# R9A09G057H register map
Vendor: Renesas Electronics; File version: 1.00
CPU: other r0p3, little endian, MPU, FPU, vendor SysTick, 4 interrupt priority bits, 480 interrupts
Registers are 32-bit, read-write, no defined reset value unless marked. A register's access mark holds for its fields unless they carry their own. Offsets are from the block's base; [hi:lo] are bit positions; lines under a group give offsets from that group; {n}, {i} and the like mark numbered series.

## R_TSU_B0 — IO define file for tsu_b.
Base 0x11000000
Same registers: R_TSU_B1 0x14002000
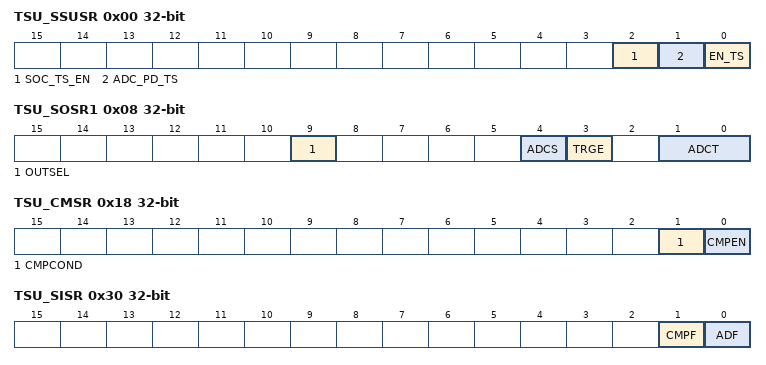
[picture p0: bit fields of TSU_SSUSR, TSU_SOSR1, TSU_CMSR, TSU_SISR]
0x00 TSU_SSUSR
  [2] SOC_TS_EN, [1] ADC_PD_TS, [0] EN_TS
0x04 TSU_STRGR
  [0] ADST wo
0x08 TSU_SOSR1
  [9] OUTSEL, [4] ADCS, [3] TRGE, [1:0] ADCT
0x10 TSU_SCRR ro
  [11:0] OUT12BIT_TS
0x14 TSU_SSR ro
  [0] CONV
0x18 TSU_CMSR
  [1] CMPCOND, [0] CMPEN
0x1C TSU_LLSR
  [11:0] LLIM
0x20 TSU_ULSR
  [11:0] ULIM
0x30 TSU_SISR ro
  [1] CMPF, [0] ADF
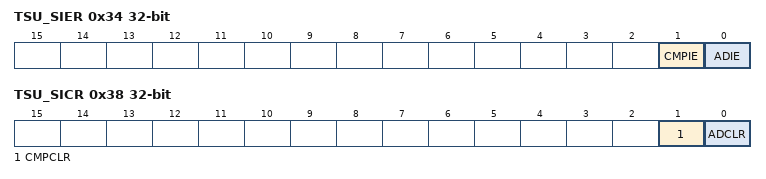
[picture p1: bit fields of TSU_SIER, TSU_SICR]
0x34 TSU_SIER
  [1] CMPIE, [0] ADIE
0x38 TSU_SICR
  [1] CMPCLR wo, [0] ADCLR wo

## R_TZC_SRAMM — IO define file for tzc.
Base 0x10460000
Same registers: R_TZC_XSPI 0x10470000, R_TZC_DDR00 0x13C60000, R_TZC_DDR01 0x13C70000, R_TZC_DDR10 0x13C80000, R_TZC_DDR11 0x13C90000, R_TZC_AXI_RCPU 0x13CA0000, R_TZC_SRAMA 0x13CB0000, R_TZC_PCIE 0x13CC0000
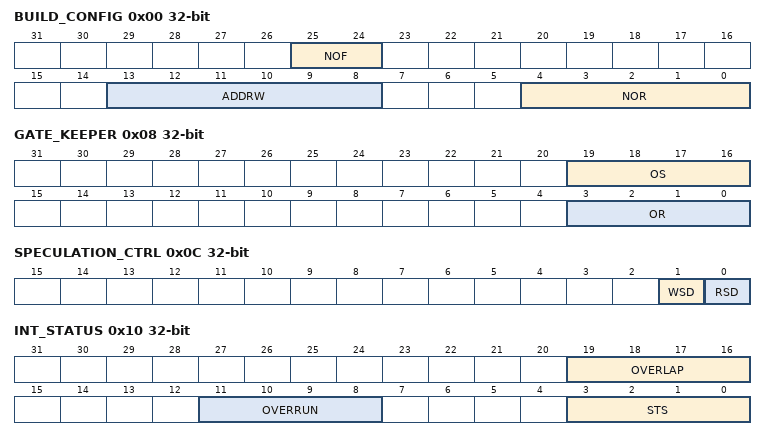
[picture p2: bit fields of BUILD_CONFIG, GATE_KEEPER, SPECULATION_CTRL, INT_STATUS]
0x00 BUILD_CONFIG ro
  [25:24] NOF, [13:8] ADDRW, [4:0] NOR
0x04 ACTION
  [1:0] RV
0x08 GATE_KEEPER
  [19:16] OS, [3:0] OR
0x0C SPECULATION_CTRL
  [1] WSD, [0] RSD
0x10 INT_STATUS ro
  [19:16] OVERLAP, [11:8] OVERRUN, [3:0] STS
0x14 INT_CLEAR wo
  [3:0] CLEAR
{0x20+0x10*i} FAIL_ADDRESS_LOW_{i} ro (i=0..3)
  [31:0] ASL
{0x24+0x10*i} FAIL_ADDRESS_HIGH_{i} ro (i=0..3)
  [0] ASH
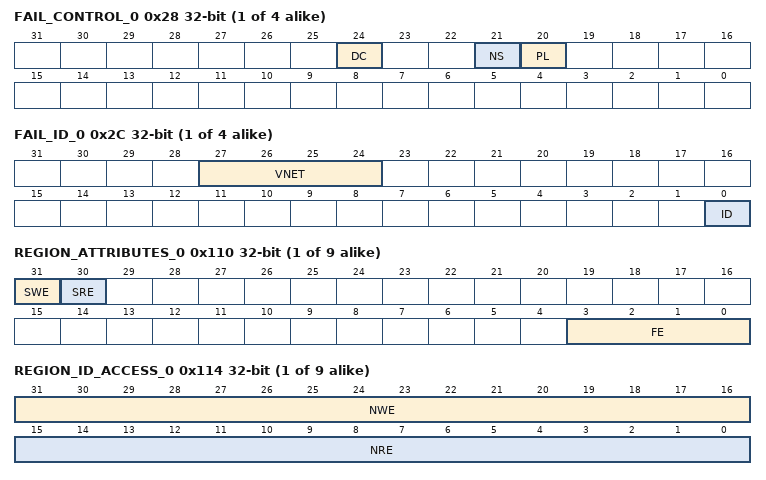
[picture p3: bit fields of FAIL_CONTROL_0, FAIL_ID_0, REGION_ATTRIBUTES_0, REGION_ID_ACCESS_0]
{0x28+0x10*i} FAIL_CONTROL_{i} ro (i=0..3)
  [24] DC, [21] NS, [20] PL
{0x2C+0x10*i} FAIL_ID_{i} ro (i=0..3)
  [27:24] VNET, [0] ID
{0x100+0x20*i} REGION_BASE_LOW_{i} ro (i=0..8)
  [31:12] BAL
0x104 REGION_BASE_HIGH_0 ro
  [0] BAH
{0x108+0x20*i} REGION_TOP_LOW_{i} ro (i=0..8)
  [31:12] TAL
0x10C REGION_TOP_HIGH_0 ro
  [0] TAH
{0x110+0x20*i} REGION_ATTRIBUTES_{i} (i=0..8)
  [31] SWE, [30] SRE, [3:0] FE
{0x114+0x20*i} REGION_ID_ACCESS_{i} (i=0..8)
  [31:16] NWE, [15:0] NRE
{0x104+0x20*i} REGION_BASE_HIGH_{i} ro (i=1..8)
  [{i}:0] BAH
{0x10C+0x20*i} REGION_TOP_HIGH_{i} ro (i=1..8)
  [{i}:0] TAH
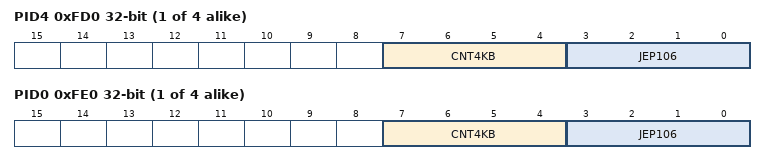
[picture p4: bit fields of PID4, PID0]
{0xFC0+4i} PID{i} ro (i=4..7)
  [7:4] CNT4KB, [3:0] JEP106
{0xFE0+4i} PID{i} ro (i=0..3)
  [7:4] CNT4KB, [3:0] JEP106
{0xFF0+4i} CID{i} ro (i=0..3)
  [7:0] CPI{i}

## R_WDT0 — IO define file for wdt.
Base 0x11C00400
Same registers: R_WDT2 0x13000000, R_WDT3 0x13000400, R_WDT1 0x14400000
0x00 WDT0_WDTRR 8-bit
  [7:0] REFRESH
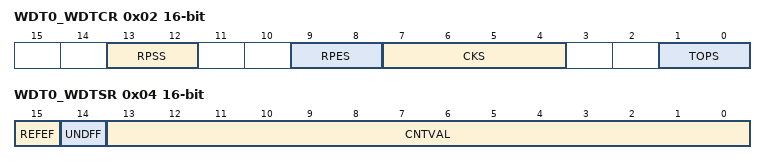
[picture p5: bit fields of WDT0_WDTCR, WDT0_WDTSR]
0x02 WDT0_WDTCR 16-bit
  [13:12] RPSS, [9:8] RPES, [7:4] CKS, [1:0] TOPS
0x04 WDT0_WDTSR 16-bit
  [15] REFEF, [14] UNDFF, [13:0] CNTVAL ro
0x06 WDT0_WDTRCR 8-bit
  [7] RSTIRQS

## R_XSPI0 — IO define file for xspi.
Base 0x11030000
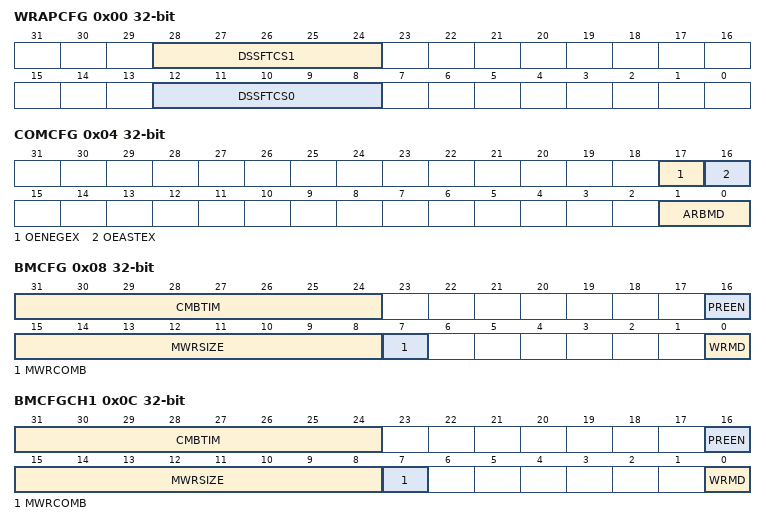
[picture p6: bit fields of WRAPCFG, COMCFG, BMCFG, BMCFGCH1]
0x00 WRAPCFG
  [28:24] DSSFTCS1, [12:8] DSSFTCS0
0x04 COMCFG
  [17] OENEGEX, [16] OEASTEX, [1:0] ARBMD
0x08 BMCFG
  [31:24] CMBTIM, [16] PREEN, [15:8] MWRSIZE, [7] MWRCOMB, [0] WRMD
0x0C BMCFGCH1
  [31:24] CMBTIM, [16] PREEN, [15:8] MWRSIZE, [7] MWRCOMB, [0] WRMD
{0x10+0x10*i} CSa[{i}] (i=0..1) group — xSPI Command Map Configuration Register [0..1]
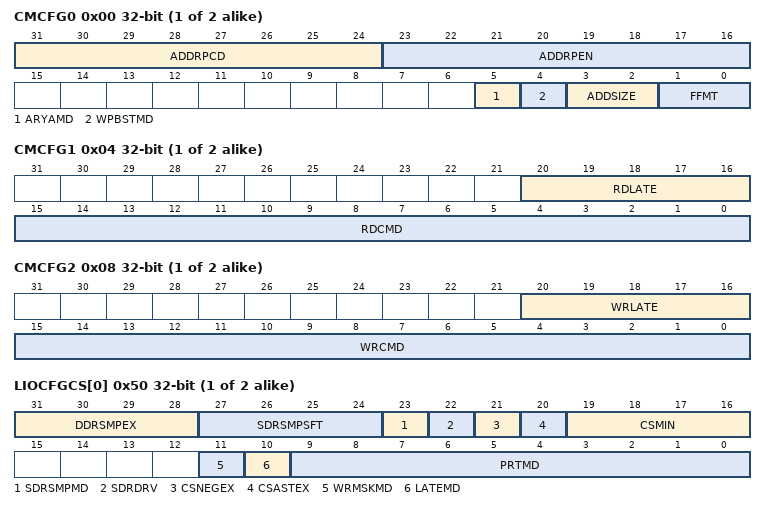
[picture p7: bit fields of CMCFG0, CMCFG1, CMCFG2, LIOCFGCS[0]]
  0x00 CMCFG0
    [31:24] ADDRPCD, [23:16] ADDRPEN, [5] ARYAMD, [4] WPBSTMD, [3:2] ADDSIZE, [1:0] FFMT
  0x04 CMCFG1
    [20:16] RDLATE, [15:0] RDCMD
  0x08 CMCFG2
    [20:16] WRLATE, [15:0] WRCMD
{0x50+4i} LIOCFGCS[{i}] (i=0..1)
  [31:28] DDRSMPEX, [27:24] SDRSMPSFT, [23] SDRSMPMD, [22] SDRDRV, [21] CSNEGEX, [20] CSASTEX, [19:16] CSMIN, [11] WRMSKMD, [10] LATEMD, [9:0] PRTMD
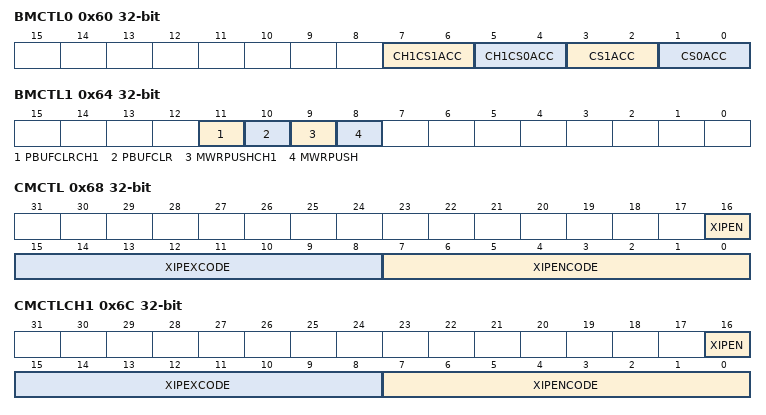
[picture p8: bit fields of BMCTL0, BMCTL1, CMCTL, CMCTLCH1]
0x60 BMCTL0
  [7:6] CH1CS1ACC, [5:4] CH1CS0ACC, [3:2] CS1ACC, [1:0] CS0ACC
0x64 BMCTL1 wo
  [11] PBUFCLRCH1, [10] PBUFCLR, [9] MWRPUSHCH1, [8] MWRPUSH
0x68 CMCTL
  [16] XIPEN, [15:8] XIPEXCODE, [7:0] XIPENCODE
0x6C CMCTLCH1
  [16] XIPEN, [15:8] XIPEXCODE, [7:0] XIPENCODE
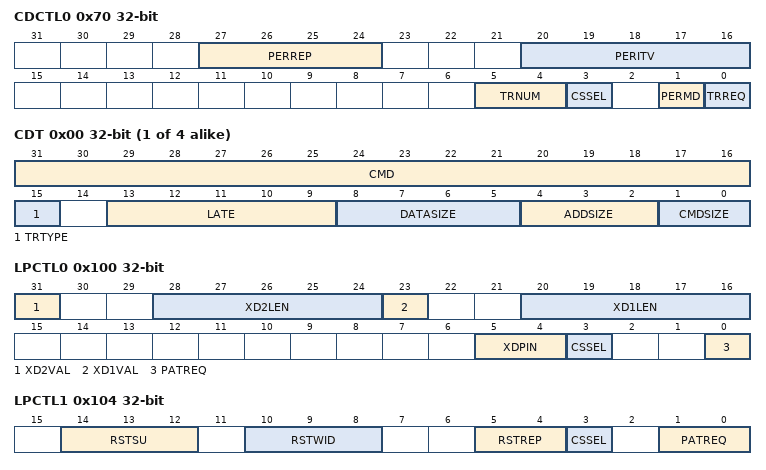
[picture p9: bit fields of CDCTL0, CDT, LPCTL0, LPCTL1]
0x70 CDCTL0
  [27:24] PERREP, [20:16] PERITV, [5:4] TRNUM, [3] CSSEL, [1] PERMD, [0] TRREQ
0x74 CDCTL1
  [31:0] PEREXP
0x78 CDCTL2
  [31:0] PERMSK
{0x80+0x10*i} BUF[{i}] (i=0..3) group — xSPI Command Manual Buf [0..3]
  0x00 CDT
    [31:16] CMD, [15] TRTYPE, [13:9] LATE, [8:5] DATASIZE, [4:2] ADDSIZE, [1:0] CMDSIZE
  0x04 CDA
    [31:0] ADD
  0x08 CDD0
    [31:0] DATA
  0x0C CDD1
    [31:0] DATA
0x100 LPCTL0
  [31] XD2VAL, [28:24] XD2LEN, [23] XD1VAL, [20:16] XD1LEN, [5:4] XDPIN, [3] CSSEL, [0] PATREQ
0x104 LPCTL1
  [14:12] RSTSU, [10:8] RSTWID, [5:4] RSTREP, [3] CSSEL, [1:0] PATREQ
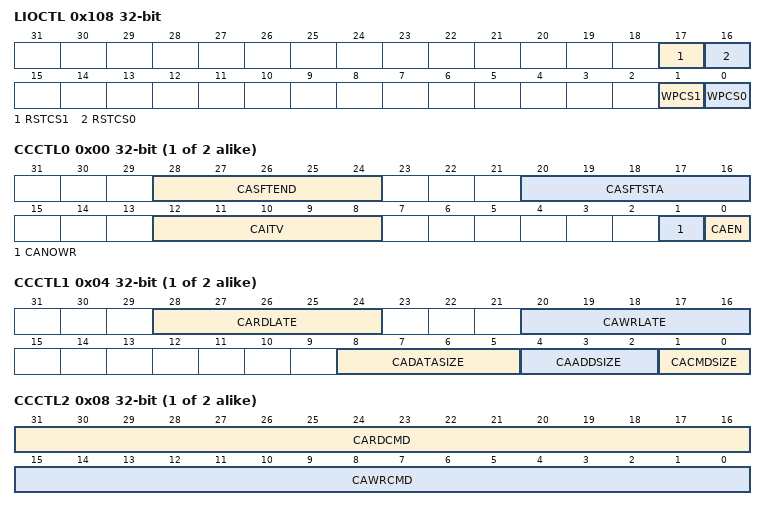
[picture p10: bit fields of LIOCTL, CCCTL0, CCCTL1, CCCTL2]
0x108 LIOCTL
  [17] RSTCS1, [16] RSTCS0, [1] WPCS1, [0] WPCS0
{0x130+0x20*i} CSb[{i}] (i=0..1) group — xSPI Command Calibration Control register [0..1]
  0x00 CCCTL0
    [28:24] CASFTEND, [20:16] CASFTSTA, [12:8] CAITV, [1] CANOWR, [0] CAEN
  0x04 CCCTL1
    [28:24] CARDLATE, [20:16] CAWRLATE, [8:5] CADATASIZE, [4:2] CAADDSIZE, [1:0] CACMDSIZE
  0x08 CCCTL2
    [31:16] CARDCMD, [15:0] CAWRCMD
  0x0C CCCTL3
    [31:0] CAADD
  {0x0+4j} CCCTL{j} (j=4..7)
    [31:0] CADATA
0x180 VERSTT ro
  [31:0] VER
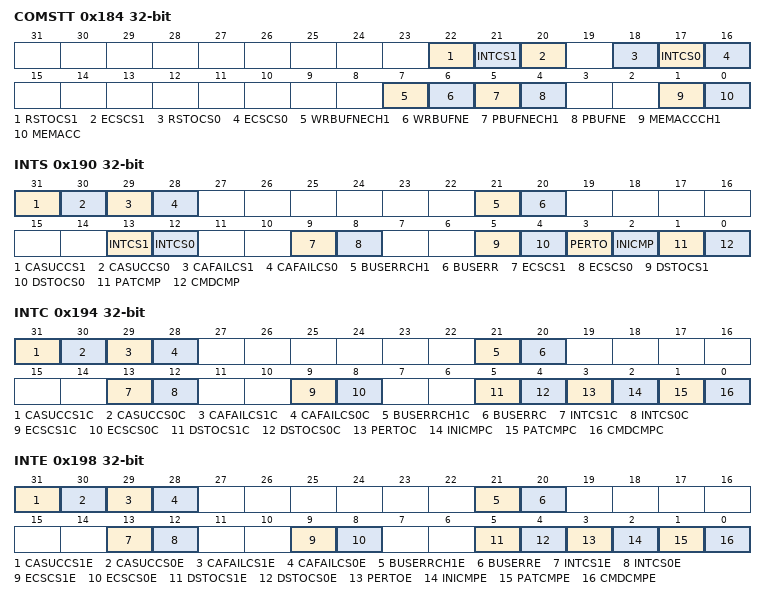
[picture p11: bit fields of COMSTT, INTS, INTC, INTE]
0x184 COMSTT ro
  [22] RSTOCS1, [21] INTCS1, [20] ECSCS1, [18] RSTOCS0, [17] INTCS0, [16] ECSCS0, [7] WRBUFNECH1, [6] WRBUFNE, [5] PBUFNECH1, [4] PBUFNE, [1] MEMACCCH1, [0] MEMACC
{0x188+4i} CASTTCS[{i}] (i=0..1) ro
  [31:0] CASUC
0x190 INTS ro
  [31] CASUCCS1, [30] CASUCCS0, [29] CAFAILCS1, [28] CAFAILCS0, [21] BUSERRCH1, [20] BUSERR, [13] INTCS1, [12] INTCS0, [9] ECSCS1, [8] ECSCS0, [5] DSTOCS1, [4] DSTOCS0, [3] PERTO, [2] INICMP, [1] PATCMP, [0] CMDCMP
0x194 INTC wo
  [31] CASUCCS1C, [30] CASUCCS0C, [29] CAFAILCS1C, [28] CAFAILCS0C, [21] BUSERRCH1C, [20] BUSERRC, [13] INTCS1C, [12] INTCS0C, [9] ECSCS1C, [8] ECSCS0C, [5] DSTOCS1C, [4] DSTOCS0C, [3] PERTOC, [2] INICMPC, [1] PATCMPC, [0] CMDCMPC
0x198 INTE
  [31] CASUCCS1E, [30] CASUCCS0E, [29] CAFAILCS1E, [28] CAFAILCS0E, [21] BUSERRCH1E, [20] BUSERRE, [13] INTCS1E, [12] INTCS0E, [9] ECSCS1E, [8] ECSCS0E, [5] DSTOCS1E, [4] DSTOCS0E, [3] PERTOE, [2] INICMPE, [1] PATCMPE, [0] CMDCMPE

## R_GLOBAL_TIMER — IO define file for global_timer.
Base 0x12C10200
0x00 GTCR_L
0x04 GTCR_H
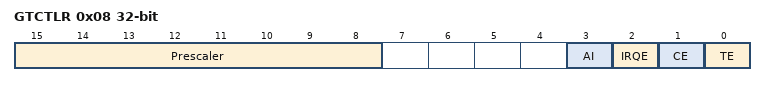
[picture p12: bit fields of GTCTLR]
0x08 GTCTLR
  [15:8] Prescaler, [3] AI, [2] IRQE, [1] CE, [0] TE
0x0C GTISR
  [0] EF
0x10 CVR_L
0x14 CVR_H
0x18 AUTO_INCR

## R_INTC_GIC — IO define file for intc_gic.
Base 0x12C10100
0x00 GICC_ICCICR
  [0] EN
0x04 GICC_ICCPMR
  [7:0] P
0x08 GICC_ICCBPR
  [2:0] BP
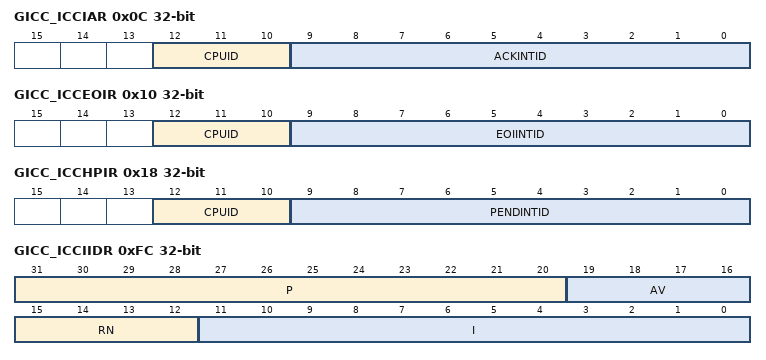
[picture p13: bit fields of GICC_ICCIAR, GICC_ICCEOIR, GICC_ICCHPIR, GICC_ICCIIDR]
0x0C GICC_ICCIAR ro
  [12:10] CPUID, [9:0] ACKINTID
0x10 GICC_ICCEOIR
  [12:10] CPUID wo, [9:0] EOIINTID wo
0x14 GICC_ICCRPR ro
  [7:0] P
0x18 GICC_ICCHPIR ro
  [12:10] CPUID, [9:0] PENDINTID
0xFC GICC_ICCIIDR ro
  [31:20] P, [19:16] AV, [15:12] RN, [11:0] I
0xF00 GICD_ICDDCR
  [0] EN
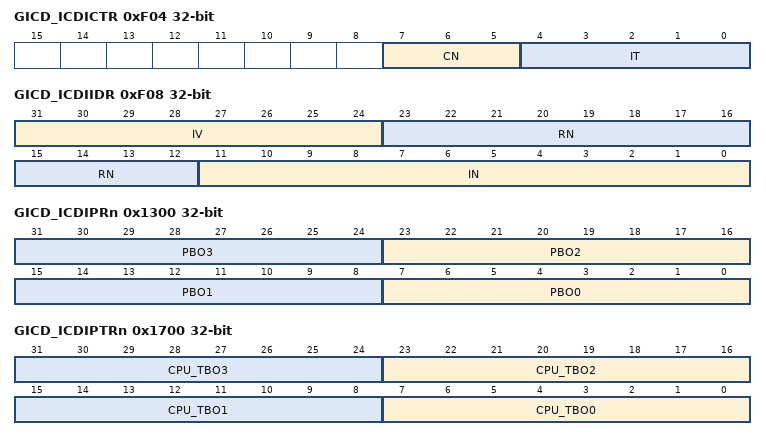
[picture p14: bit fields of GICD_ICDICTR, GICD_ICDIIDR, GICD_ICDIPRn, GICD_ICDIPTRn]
0xF04 GICD_ICDICTR ro
  [7:5] CN, [4:0] IT
0xF08 GICD_ICDIIDR ro
  [31:24] IV, [23:12] RN, [11:0] IN
0x1000 GICD_ICDISERn
  [31:0] SEB
0x1080 GICD_ICDICERn
  [31:0] CEB
0x1100 GICD_ICDISPRn
  [31:0] CPB
0x1180 GICD_ICDICPRn
  [31:0] CPB
0x1200 GICD_ICDABRn ro
  [31:0] AB
0x1300 GICD_ICDIPRn
  [8n+7:8n] PBO{n} (n=0..3)
0x1700 GICD_ICDIPTRn
  [8n+7:8n] CPU_TBO{n} (n=0..3)
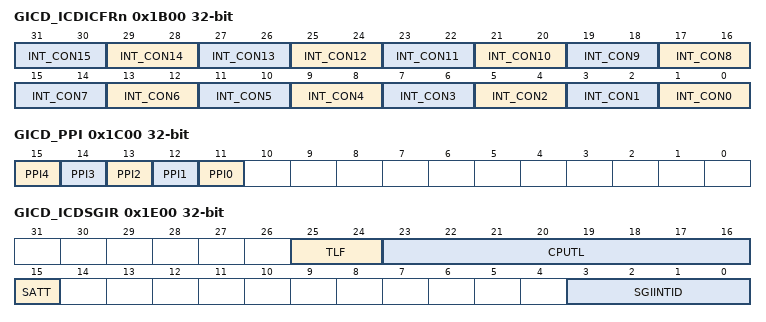
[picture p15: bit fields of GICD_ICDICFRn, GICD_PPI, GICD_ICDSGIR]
0x1B00 GICD_ICDICFRn
  [2n+1:2n] INT_CON{n} (n=0..15)
0x1C00 GICD_PPI
  [n+11] PPI{n} (n=0..4)
0x1C04 GICD_SPI ro
0x1E00 GICD_ICDSGIR
  [25:24] TLF, [23:16] CPUTL, [15] SATT, [3:0] SGIINTID
0x1ED0 GICD_PIR4 8-bit ro
  [7:0] ID
{0x1EE0+4i} GICD_PIR{i} 8-bit ro (i=0..3)
  [7:0] ID
{0x1EF0+4i} GICD_CIR{i} 8-bit ro (i=0..3)
  [7:0] ID

## R_PRIVATE_TIMER — IO define file for private_timer.
Base 0x12C10600
0x00 PTLR
0x04 PTCR
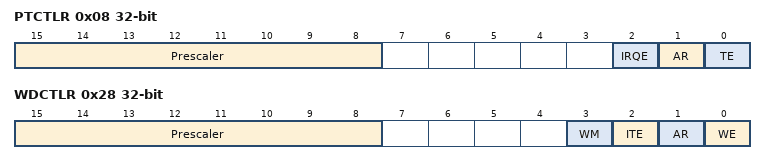
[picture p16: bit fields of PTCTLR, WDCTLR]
0x08 PTCTLR
  [15:8] Prescaler, [2] IRQE, [1] AR, [0] TE
0x0C PTISR
  [0] FLAG ro, [0] CLR wo
0x20 WDWLR
0x24 WDWCR
0x28 WDCTLR
  [15:8] Prescaler, [3] WM, [2] ITE, [1] AR, [0] WE
0x2C WDISR
  [0] FLAG ro, [0] CLR wo
0x30 WDRSR
  [0] RESET
0x34 WDDR wo

## R_SCU — IO define file for scu.
Base 0x12C10000
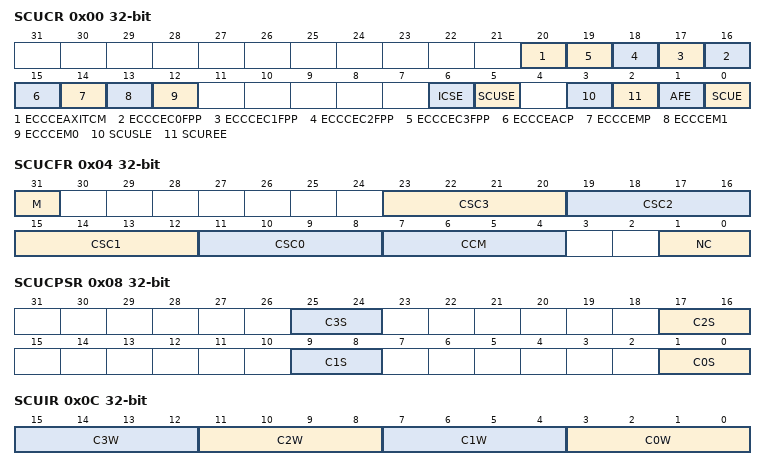
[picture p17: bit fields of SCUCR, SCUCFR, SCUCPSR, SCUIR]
0x00 SCUCR
  [20] ECCCEAXITCM, [n+16] ECCCEC{n}FPP (n=0..3), [15] ECCCEACP, [14] ECCCEMP, [13] ECCCEM1, [12] ECCCEM0, [6] ICSE, [5] SCUSE, [3] SCUSLE, [2] SCUREE, [1] AFE, [0] SCUE
0x04 SCUCFR
  [31] M, [4n+11:4n+8] CSC{n} (n=0..3), [7:4] CCM, [1:0] NC
0x08 SCUCPSR
  [8n+1:8n] C{n}S (n=0..3)
0x0C SCUIR
  [4n+3:4n] C{n}W (n=0..3)
0x40 MFSAR
  [31:20] FSA ro
0x44 MFEAR
  [31:20] FEA ro
0x48 PFSAR
  [31:20] FSA ro
0x4C PFEAR
  [31:20] FEA ro
0x50 SCUACR
  [n] C{n}SCUA (n=0..3)
0x60 SCUEBFER
  [4n+19:4n+16] WFC{n} (n=0..3), [0] STS
0x64 SCUEBSER
  [31:16] WAYS, [13:5] INDEX, [1:0] STS
0x70 SCUDTROR
  [31:30] SCURW, [25:24] SCURC, [13:5] SCURS, [0] RW
0x74 SCUDTRDVR
  [22] VALID, [21:17] VM
0x78 SCUDTRECR
  [6:0] CHUNK
0x7C ECCFER
  [8] EFED, [n] EFEDC{n} (n=0..3)
{0x80+8i} FPPFSAR{i} (i=0..3)
  [31:20] FSA
{0x84+8i} FPPFEAR{i} (i=0..3)
  [31:20] FEA
